AUTOSAR XML (schema 4-2-2)
package /VariantSubsystemModel3_pkg/VariantSubsystemModel3_swc
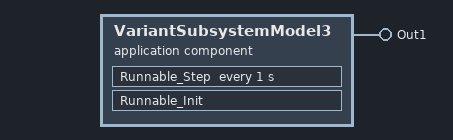
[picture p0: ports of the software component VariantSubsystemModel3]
  application sw component type VariantSubsystemModel3
    provide port Out1: nonqueued-sender-com-spec{data-element=Out1, init-value=constant-reference={short-label=DefaultInitValue_Double, constant=DefaultInitValue_Double}}, provided-interface=Out1
    behavior VariantSubsystemModel3: handle-termination-and-restart=NO-SUPPORT
      timing event Event_Runnable_Step: start-on-event=Runnable_Step, period=1
      runnable Runnable_Init
      runnable Runnable_Step
        data-write-access:
          access OUT_Out1_Out1: accessed-variable=Out1.Out1
